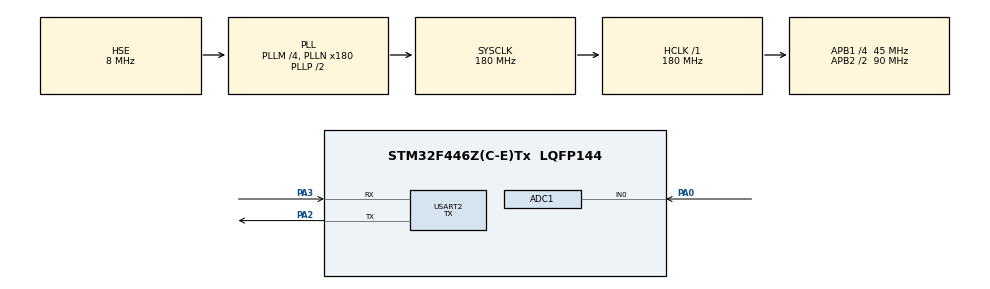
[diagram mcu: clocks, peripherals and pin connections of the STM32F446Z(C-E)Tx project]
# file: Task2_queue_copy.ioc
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ADC1.Channel-0\#ChannelRegularConversion=ADC_CHANNEL_0
ADC1.Channel-1\#ChannelRegularConversion=ADC_CHANNEL_TEMPSENSOR
ADC1.ContinuousConvMode=ENABLE
ADC1.ExternalTrigConv=ADC_EXTERNALTRIGCONV_T8_TRGO
ADC1.InjNumberOfConversion=0
ADC1.NbrOfConversion=2
ADC1.NbrOfConversionFlag=1
ADC1.Rank-0\#ChannelRegularConversion=1
ADC1.Rank-1\#ChannelRegularConversion=2
ADC1.SamplingTime-0\#ChannelRegularConversion=ADC_SAMPLETIME_3CYCLES
ADC1.SamplingTime-1\#ChannelRegularConversion=ADC_SAMPLETIME_480CYCLES
ADC1.ScanConvMode=ENABLE
ADC1.master=1
Dma.ADC1.0.Direction=DMA_PERIPH_TO_MEMORY
Dma.ADC1.0.FIFOMode=DMA_FIFOMODE_DISABLE
Dma.ADC1.0.Instance=DMA2_Stream0
Dma.ADC1.0.MemDataAlignment=DMA_MDATAALIGN_HALFWORD
Dma.ADC1.0.MemInc=DMA_MINC_ENABLE
Dma.ADC1.0.Mode=DMA_CIRCULAR
Dma.ADC1.0.PeriphDataAlignment=DMA_PDATAALIGN_HALFWORD
Dma.ADC1.0.PeriphInc=DMA_PINC_DISABLE
Dma.ADC1.0.Priority=DMA_PRIORITY_HIGH
Dma.Request0=ADC1
FREERTOS.Queues01=ADCqueue,16,uint16_t,0,Dynamic,NULL,NULL
FREERTOS.Tasks01=ADC_READ_POLL,0,128,ADC_READ,Default,NULL,Dynamic,NULL,NULL;ADC_Task,-3,256,ADC_Tasks,Default,NULL,Dynamic,NULL,NULL;UART_Task,0,128,UART_transmission,Default,NULL,Dynamic,NULL,NULL
FREERTOS.configCHECK_FOR_STACK_OVERFLOW=2
FREERTOS.configENABLE_FPU=1
FREERTOS.configRECORD_STACK_HIGH_ADDRESS=1
FREERTOS.configUSE_NEWLIB_REENTRANT=0
FREERTOS.configUSE_POSIX_ERRNO=1
FREERTOS.configUSE_TIMERS=1
Mcu.Family=STM32F4
Mcu.Name=STM32F446Z(C-E)Tx
Mcu.Package=LQFP144
NVIC.ADC_IRQn=true\:5\:0\:false\:false\:true\:true\:true\:true\:true
NVIC.DMA2_Stream0_IRQn=true\:5\:0\:false\:false\:true\:true\:false\:true\:true
NVIC.PriorityGroup=NVIC_PRIORITYGROUP_4
NVIC.TIM1_UP_TIM10_IRQn=true\:5\:0\:true\:false\:true\:false\:false\:true\:true
NVIC.TIM8_BRK_TIM12_IRQn=true\:5\:0\:false\:false\:true\:true\:true\:true\:true
NVIC.TIM8_CC_IRQn=true\:5\:0\:false\:false\:true\:true\:true\:true\:true
NVIC.TIM8_TRG_COM_TIM14_IRQn=true\:5\:0\:false\:false\:true\:true\:true\:true\:true
NVIC.TIM8_UP_TIM13_IRQn=true\:5\:0\:false\:false\:true\:true\:true\:true\:true
NVIC.TimeBase=TIM1_UP_TIM10_IRQn
NVIC.TimeBaseIP=TIM10
NVIC.USART2_IRQn=true\:5\:0\:true\:false\:true\:true\:true\:true\:true
PA0-WKUP.Signal=ADCx_IN0
PA13.Mode=Serial_Wire
PA13.Signal=SYS_JTMS-SWDIO
PA14.Mode=Serial_Wire
PA14.Signal=SYS_JTCK-SWCLK
PA2.Mode=Asynchronous
PA2.Signal=USART2_TX
PA3.Mode=Asynchronous
PA3.Signal=USART2_RX
PH0-OSC_IN.Mode=HSE-External-Oscillator
PH0-OSC_IN.Signal=RCC_OSC_IN
PH1-OSC_OUT.Mode=HSE-External-Oscillator
PH1-OSC_OUT.Signal=RCC_OSC_OUT
ProjectManager.HeapSize=0x200
ProjectManager.StackSize=0x400
ProjectManager.TargetToolchain=STM32CubeIDE
RCC.48MHZClocksFreq_Value=24000000
RCC.AHBFreq_Value=180000000
RCC.APB1CLKDivider=RCC_HCLK_DIV4
RCC.APB1Freq_Value=45000000
RCC.APB1TimFreq_Value=90000000
RCC.APB2CLKDivider=RCC_HCLK_DIV2
RCC.APB2Freq_Value=90000000
RCC.APB2TimFreq_Value=180000000
RCC.CortexFreq_Value=180000000
RCC.HCLKFreq_Value=180000000
RCC.HSE_VALUE=8000000
RCC.HSI_VALUE=16000000
RCC.PLLM=4
RCC.PLLMUL=RCC_PLL_MUL9
RCC.PLLN=180
RCC.PLLQ=7
RCC.PLLSourceVirtual=RCC_PLLSOURCE_HSE
RCC.PRESCALERUSB=RCC_USBCLKSOURCE_PLL_DIV1_5
RCC.SYSCLKFreq_VALUE=180000000
RCC.SYSCLKSource=RCC_SYSCLKSOURCE_PLLCLK
RCC.SYSCLKSourceVirtual=RCC_SYSCLKSOURCE_PLLCLK
RCC.USBFreq_Value=51428571.428571425
RCC.VCOOutputFreq_Value=360000000
SH.ADCx_IN0.0=ADC1_IN0,IN0
TIM8.Period=199
TIM8.Prescaler=899
TIM8.TIM_MasterOutputTrigger=TIM_TRGO_UPDATE
USART2.Mode=MODE_TX
USART2.VirtualMode=VM_ASYNC
VP_ADC1_TempSens_Input.Mode=IN-TempSens
VP_FREERTOS_VS_CMSIS_V1.Mode=CMSIS_V1
VP_SYS_VS_tim10.Mode=TIM10
VP_TIM8_VS_ClockSourceINT.Mode=Internal
board=NUCLEO-F446ZE

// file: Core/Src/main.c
/* USER CODE BEGIN Header */
/**
  ******************************************************************************
  * @file           : main.c
  * @brief          : Main program body
  ******************************************************************************
  * @attention
  *
  * Copyright (c) 2023 STMicroelectronics.
  * All rights reserved.
  *
  * This software is licensed under terms that can be found in the LICENSE file
  * in the root directory of this software component.
  * If no LICENSE file comes with this software, it is provided AS-IS.
  *
  ******************************************************************************
  */
/* USER CODE END Header */
#include "main.h"
#include "cmsis_os.h"
#include "adc.h"
#include "dma.h"
#include "tim.h"
#include "usart.h"
#include "gpio.h"

/* USER CODE BEGIN Includes */
#include "string.h"
/* USER CODE END Includes */

/* USER CODE BEGIN PV */
extern SemaphoreHandle_t mutex;
extern uint16_t DMA_Buffer[2];

extern UART_HandleTypeDef huart2;
char entry[]="Datas are shown\n";
/* USER CODE END PV */

void SystemClock_Config(void);
void MX_FREERTOS_Init(void);

int main(void)
{

  /* MCU Configuration--------------------------------------------------------*/

  /* Reset of all peripherals, Initializes the Flash interface and the Systick. */
  HAL_Init();

  /* Configure the system clock */
  SystemClock_Config();

  /* Initialize all configured peripherals */
  MX_GPIO_Init();
  MX_DMA_Init();
  MX_ADC1_Init();
  MX_TIM8_Init();
  MX_USART2_UART_Init();
  /* USER CODE BEGIN 2 */
  HAL_TIM_Base_Start(&htim8);

  HAL_ADC_Start_DMA(&hadc1,(uint32_t*) DMA_Buffer, 2);
  HAL_ADC_Start_IT(&hadc1);

  /* USER CODE END 2 */

  /* Call init function for freertos objects (in freertos.c) */
  MX_FREERTOS_Init();

  /* Start scheduler */
  osKernelStart();

  /* We should never get here as control is now taken by the scheduler */
  /* Infinite loop */
  while (1)
  {

  }
}

void SystemClock_Config(void)
{
  RCC_OscInitTypeDef RCC_OscInitStruct = {0};
  RCC_ClkInitTypeDef RCC_ClkInitStruct = {0};

  /** Configure the main internal regulator output voltage
  */
  __HAL_RCC_PWR_CLK_ENABLE();
  __HAL_PWR_VOLTAGESCALING_CONFIG(PWR_REGULATOR_VOLTAGE_SCALE1);

  /** Initializes the RCC Oscillators according to the specified parameters
  * in the RCC_OscInitTypeDef structure.
  */
  RCC_OscInitStruct.OscillatorType = RCC_OSCILLATORTYPE_HSE;
  RCC_OscInitStruct.HSEState = RCC_HSE_ON;
  RCC_OscInitStruct.PLL.PLLState = RCC_PLL_ON;
  RCC_OscInitStruct.PLL.PLLSource = RCC_PLLSOURCE_HSE;
  RCC_OscInitStruct.PLL.PLLM = 4;
  RCC_OscInitStruct.PLL.PLLN = 180;
  RCC_OscInitStruct.PLL.PLLP = RCC_PLLP_DIV2;
  RCC_OscInitStruct.PLL.PLLQ = 7;
  RCC_OscInitStruct.PLL.PLLR = 2;
  if (HAL_RCC_OscConfig(&RCC_OscInitStruct) != HAL_OK)
  {
    Error_Handler();
  }

  /** Activate the Over-Drive mode
  */
  if (HAL_PWREx_EnableOverDrive() != HAL_OK)
  {
    Error_Handler();
  }

  /** Initializes the CPU, AHB and APB buses clocks
  */
  RCC_ClkInitStruct.ClockType = RCC_CLOCKTYPE_HCLK|RCC_CLOCKTYPE_SYSCLK
                              |RCC_CLOCKTYPE_PCLK1|RCC_CLOCKTYPE_PCLK2;
  RCC_ClkInitStruct.SYSCLKSource = RCC_SYSCLKSOURCE_PLLCLK;
  RCC_ClkInitStruct.AHBCLKDivider = RCC_SYSCLK_DIV1;
  RCC_ClkInitStruct.APB1CLKDivider = RCC_HCLK_DIV4;
  RCC_ClkInitStruct.APB2CLKDivider = RCC_HCLK_DIV2;

  if (HAL_RCC_ClockConfig(&RCC_ClkInitStruct, FLASH_LATENCY_5) != HAL_OK)
  {
    Error_Handler();
  }
}

void HAL_TIM_PeriodElapsedCallback(TIM_HandleTypeDef *htim)
{
  if (htim->Instance == TIM10) {
    HAL_IncTick();
  }
}

void Error_Handler(void)
{
  __disable_irq();
  while (1)
  {
  }
}

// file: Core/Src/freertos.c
/* USER CODE BEGIN Header */
/**
  ******************************************************************************
  * File Name          : freertos.c
  * Description        : Code for freertos applications
  ******************************************************************************
  * @attention
  *
  * Copyright (c) 2023 STMicroelectronics.
  * All rights reserved.
  *
  * This software is licensed under terms that can be found in the LICENSE file
  * in the root directory of this software component.
  * If no LICENSE file comes with this software, it is provided AS-IS.
  *
  ******************************************************************************
  */
/* USER CODE END Header */

#include "FreeRTOS.h"
#include "task.h"
#include "main.h"
#include "cmsis_os.h"

/* USER CODE BEGIN Includes */
#include "adc.h"
#include "string.h"
#include "stdio.h"
#include "usart.h"
extern ADC_HandleTypeDef hadc;
extern UART_HandleTypeDef huart2;
/* USER CODE END Includes */

/* USER CODE BEGIN PTD */

typedef struct ADC_READ_STRUCT{
	uint32_t channel_no;
	float Channel_0_Value;
	uint16_t Channel_Temp_Value;
}ADC_t;

uint16_t DMA_Buffer[2];
/* USER CODE END PTD */

/* USER CODE BEGIN PD */
#define VREF 3.3f
#define ADC_RESOLUTION 4095.0f
#define LM35_SCALE_FACTOR 0.01f
#define TEMP_SAMPLES 10
/* USER CODE END PD */

/* USER CODE BEGIN Variables */
extern ADC_HandleTypeDef hadc1;
float resolution = VREF / ADC_RESOLUTION;
float Temperature=0.0;
float TVoltage,CVoltage;
SemaphoreHandle_t mutex;
ADC_t Poll_Data={0};
ADC_t Glob_Data={0};
ADC_t Avg_data;

QueueHandle_t ADCtoUARTqueueHandle;	/* Queue definitions are Here...*/
QueueHandle_t ADCqueue_t;

float temp_array[TEMP_SAMPLES];
float temp_sum = 0.0f;
int temp_index = 0;
/* USER CODE END Variables */
osThreadId ADC_READ_POLLHandle;
osThreadId ADC_TaskHandle;
osThreadId UART_TaskHandle;
osMessageQId ADCqueueHandle;

void ADC_READ(void const * argument);
void ADC_Tasks(void const * argument);
void UART_transmission(void const * argument);

void MX_FREERTOS_Init(void); /* (MISRA C 2004 rule 8.1) */

/* GetIdleTaskMemory prototype (linked to static allocation support) */
void vApplicationGetIdleTaskMemory( StaticTask_t **ppxIdleTaskTCBBuffer, StackType_t **ppxIdleTaskStackBuffer, uint32_t *pulIdleTaskStackSize );

/* GetTimerTaskMemory prototype (linked to static allocation support) */
void vApplicationGetTimerTaskMemory( StaticTask_t **ppxTimerTaskTCBBuffer, StackType_t **ppxTimerTaskStackBuffer, uint32_t *pulTimerTaskStackSize );

/* Hook prototypes */
void vApplicationStackOverflowHook(xTaskHandle xTask, signed char *pcTaskName);

/* USER CODE BEGIN 4 */
__weak void vApplicationStackOverflowHook(xTaskHandle xTask, signed char *pcTaskName)
{
   /* Run time stack overflow checking is performed if
   configCHECK_FOR_STACK_OVERFLOW is defined to 1 or 2. This hook function is
   called if a stack overflow is detected. */
}
/* USER CODE END 4 */

/* USER CODE BEGIN GET_IDLE_TASK_MEMORY */
static StaticTask_t xIdleTaskTCBBuffer;
static StackType_t xIdleStack[configMINIMAL_STACK_SIZE];

void vApplicationGetIdleTaskMemory( StaticTask_t **ppxIdleTaskTCBBuffer, StackType_t **ppxIdleTaskStackBuffer, uint32_t *pulIdleTaskStackSize )
{
  *ppxIdleTaskTCBBuffer = &xIdleTaskTCBBuffer;
  *ppxIdleTaskStackBuffer = &xIdleStack[0];
  *pulIdleTaskStackSize = configMINIMAL_STACK_SIZE;
  /* place for user code */
}
/* USER CODE END GET_IDLE_TASK_MEMORY */

/* USER CODE BEGIN GET_TIMER_TASK_MEMORY */
static StaticTask_t xTimerTaskTCBBuffer;
static StackType_t xTimerStack[configTIMER_TASK_STACK_DEPTH];

void vApplicationGetTimerTaskMemory( StaticTask_t **ppxTimerTaskTCBBuffer, StackType_t **ppxTimerTaskStackBuffer, uint32_t *pulTimerTaskStackSize )
{
  *ppxTimerTaskTCBBuffer = &xTimerTaskTCBBuffer;
  *ppxTimerTaskStackBuffer = &xTimerStack[0];
  *pulTimerTaskStackSize = configTIMER_TASK_STACK_DEPTH;
  /* place for user code */
}
/* USER CODE END GET_TIMER_TASK_MEMORY */

void MX_FREERTOS_Init(void) {
  /* USER CODE BEGIN Init */
	 for (int i = 0; i < TEMP_SAMPLES; i++)
	    {
	        temp_array[i] = 0.0f;
	    }
  /* USER CODE END Init */

  /* USER CODE BEGIN RTOS_MUTEX */

	mutex = xSemaphoreCreateMutex();
  /* USER CODE END RTOS_MUTEX */

  /* Create the queue(s) */
  /* definition and creation of ADCqueue */
  osMessageQDef(ADCqueue, 16, uint16_t);
  ADCqueueHandle = osMessageCreate(osMessageQ(ADCqueue), NULL);

  /* USER CODE BEGIN RTOS_QUEUES */

  /* add queues, ... */
  ADCqueue_t = xQueueCreate(10, sizeof(ADC_t));
  if(ADCqueue_t==NULL){
	  //Queue error;
  }
  ADCtoUARTqueueHandle = xQueueCreate(10, sizeof(ADC_t));

  if (ADCtoUARTqueueHandle == NULL) {
	  //Queue error;
  }

  /* USER CODE END RTOS_QUEUES */

  /* Create the thread(s) */
  /* definition and creation of ADC_READ_POLL */
  osThreadDef(ADC_READ_POLL, ADC_READ, osPriorityNormal, 0, 128);
  ADC_READ_POLLHandle = osThreadCreate(osThread(ADC_READ_POLL), NULL);

  /* definition and creation of ADC_Task */
  osThreadDef(ADC_Task, ADC_Tasks, osPriorityIdle, 0, 256);
  ADC_TaskHandle = osThreadCreate(osThread(ADC_Task), NULL);

  /* definition and creation of UART_Task */
  osThreadDef(UART_Task, UART_transmission, osPriorityNormal, 0, 128);
  UART_TaskHandle = osThreadCreate(osThread(UART_Task), NULL);

}

void ADC_READ(void const * argument)
{
  /* USER CODE BEGIN ADC_READ */
  /* Infinite loop */
//	ADC_t Poll_datas;
//	BaseType_t sendResult;

  for(;;)
  {

//		ADC_Select_CH0();
//		HAL_ADC_Start(&hadc1);
//		HAL_ADC_PollForConversion(&hadc1, 1000);
//		Poll_datas.Channel_0_Value=HAL_ADC_GetValue(&hadc1);
//		HAL_ADC_Stop(&hadc1);
//
//		ADC_Select_CHTemp();
//		HAL_ADC_Start(&hadc1);
//		HAL_ADC_PollForConversion(&hadc1, 1000);
//		Poll_datas.Channel_Temp_Value=HAL_ADC_GetValue(&hadc1);
//		HAL_ADC_Stop(&hadc1);
//		sendResult = xQueueSend(ADCqueue_t, (void *)&Poll_datas, pdMS_TO_TICKS(100));
//		if(sendResult !=pdPASS){
//			Error_Handler();
//		}
		osDelay(100);

  }
  /* USER CODE END ADC_READ */
}

void ADC_Tasks(void const * argument)
{
  /* USER CODE BEGIN ADC_Tasks */
  /* Infinite loop */
	ADC_t Datas;
	uint16_t custom_pin = 0, tmps = 0;
	uint8_t  channel;
	const float V25 = 0.76f;
	const float Avg_Slope = 0.0025f;

	for (;;)
	{
		 if (xQueueReceive(ADCqueue_t, &Datas, portMAX_DELAY) == pdPASS)
			    {

					channel=Datas.channel_no;
					Avg_data.channel_no=channel;

					custom_pin=Datas.Channel_0_Value;
					CVoltage = (float)custom_pin * resolution;

					Avg_data.Channel_0_Value=CVoltage;

					tmps = Datas.Channel_Temp_Value;
					float TVoltage = (float)tmps * resolution;
					float Temperature = (TVoltage - V25) / Avg_Slope + 25;

					temp_sum = temp_sum - temp_array[temp_index] + Temperature;
					temp_array[temp_index] = Temperature;
					temp_index = (temp_index + 1) % TEMP_SAMPLES;
					float temp_avg = temp_sum / TEMP_SAMPLES;

					Avg_data.channel_no = 1;
					Avg_data.Channel_Temp_Value = temp_avg;
					BaseType_t sendResult;

					sendResult = xQueueSend(ADCtoUARTqueueHandle, (void *)&Avg_data, pdMS_TO_TICKS(100));
					if (sendResult != pdPASS) {
							// Failed to send the data to the queue
					}

			    }

	  vTaskDelay(pdMS_TO_TICKS(100));

  }
  /* USER CODE END ADC_Tasks */
}

void UART_transmission(void const * argument)
{
  /* USER CODE BEGIN UART_transmission */
  /* Infinite loop */
	 ADC_t Received_Data;
	 char Uart_Data[50]="";
	 uint8_t results;
  for(;;)
  {

	  if (xQueueReceive(ADCtoUARTqueueHandle, &Received_Data, pdMS_TO_TICKS(100)) == pdPASS) {

	      // Print the data to the terminal
		  sprintf(Uart_Data,"Channel_0 Voltage: %d\nTemperature: %d°C\n",
				  (uint16_t)Received_Data.Channel_0_Value,
				  Received_Data.Channel_Temp_Value);
		 results= HAL_UART_Transmit_IT(&huart2, (uint8_t*)Uart_Data, strlen(Uart_Data));
		 if(results != HAL_OK){
			 Error_Handler();
		 }
	  }
	  vTaskDelay(pdMS_TO_TICKS(1000));

  }
  /* USER CODE END UART_transmission */
}

/* USER CODE BEGIN Application */

void HAL_ADC_ConvCpltCallback(ADC_HandleTypeDef* hadc) {

    BaseType_t xHigherPriorityTaskWoken = pdFALSE; // define xHigherPriorityTaskWoken as local variable
    if (hadc->Instance == ADC1) {
        HAL_ADC_Start_DMA(hadc, (uint32_t*) DMA_Buffer, 2);
        uint16_t* pData = DMA_Buffer;
        Glob_Data.Channel_0_Value = pData[1];
        Glob_Data.Channel_Temp_Value = pData[0];
        xQueueSendFromISR(ADCqueue_t, (void *)&Glob_Data, &xHigherPriorityTaskWoken); // send data to queue
    }
}

void HAL_UART_TxCpltCallback(UART_HandleTypeDef *huart)
{
    if (huart == &huart2)
    {
        // USART2 transmission complete callback

        // Do nothing in this case
    }
}

/* USER CODE END Application */
